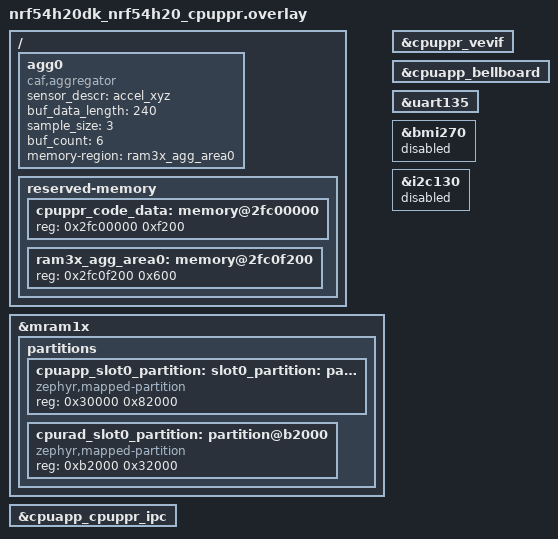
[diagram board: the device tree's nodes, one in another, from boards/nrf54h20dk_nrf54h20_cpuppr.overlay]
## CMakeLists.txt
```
#
# Copyright (c) 2024 Nordic Semiconductor ASA
#
# SPDX-License-Identifier: LicenseRef-Nordic-5-Clause
#

cmake_minimum_required(VERSION 3.20.0)

################################################################################

find_package(Zephyr REQUIRED HINTS $ENV{ZEPHYR_BASE})

if(NOT EXISTS "${CMAKE_CURRENT_SOURCE_DIR}/configuration/${NORMALIZED_BOARD_TARGET}")
  message(FATAL_ERROR
          "Board ${BOARD} is not supported.\n"
          "Please make sure board specific configuration files are added to "
          "${CMAKE_CURRENT_SOURCE_DIR}/configuration/${BOARD}")
endif()

set(REMOTE_INC_DIR "${CMAKE_CURRENT_SOURCE_DIR}/configuration/${NORMALIZED_BOARD_TARGET}")
string(CONFIGURE ${REMOTE_INC_DIR} REMOTE_INC_DIR)

project(remote)

target_sources(app PRIVATE src/main.c)

# Add include directory for board specific CAF def files
zephyr_include_directories(
  ../configuration/common
  /configuration
  ${REMOTE_INC_DIR}
)

# Add subdirectory from common part.
add_subdirectory(../common/src/modules ${CMAKE_CURRENT_BINARY_DIR}/common/src/module)
```

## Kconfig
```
#
# Copyright (c) 2024 Nordic Semiconductor ASA
#
# SPDX-License-Identifier: LicenseRef-Nordic-5-Clause
#

menu "Machine learning application (remote core)"

rsource "../common/Kconfig"

endmenu

menu "Zephyr Kernel"
source "Kconfig.zephyr"
endmenu
```

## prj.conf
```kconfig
#
# Copyright (c) 2024 Nordic Semiconductor ASA
#
# SPDX-License-Identifier: LicenseRef-Nordic-5-Clause
#
################################################################################
# Application configuration

CONFIG_CAF=y

CONFIG_CAF_INIT_LOG_SENSOR_EVENTS=n

CONFIG_CAF_SENSOR_MANAGER=y

CONFIG_APP_EVENT_MANAGER=y
CONFIG_EVENT_MANAGER_PROXY=y
CONFIG_HEAP_MEM_POOL_SIZE=4096
CONFIG_REBOOT=y

CONFIG_SENSOR=y

CONFIG_IPC_SERVICE=y
CONFIG_MBOX=y

################################################################################
# Debug configuration

CONFIG_ASSERT=y
CONFIG_RESET_ON_FATAL_ERROR=n

CONFIG_LOG=y
```

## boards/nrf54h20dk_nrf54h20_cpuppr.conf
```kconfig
#
# Copyright (c) 2024 Nordic Semiconductor ASA
#
# SPDX-License-Identifier: LicenseRef-Nordic-5-Clause
#
################################################################################
# Application configuration

CONFIG_ML_APP_SENSOR_EVENT_DESCR="accel_xyz"

CONFIG_ML_APP_EVENT_PROXY=y
CONFIG_ML_APP_REMOTE_CORE_INITIALIZATION_TIMEOUT=10000

CONFIG_SIZE_OPTIMIZATIONS=y

################################################################################
# System configuration

CONFIG_TIMESLICING=n

# LIBC minimal configuration
CONFIG_MINIMAL_LIBC=y
CONFIG_MINIMAL_LIBC_TIME=n
CONFIG_COMMON_LIBC_MALLOC=n
CONFIG_MINIMAL_LIBC_NON_REENTRANT_FUNCTIONS=n

CONFIG_HEAP_MEM_POOL_SIZE=512
CONFIG_EVENT_MANAGER_PROXY=y
# Higher timouts are required.
CONFIG_EVENT_MANAGER_PROXY_BIND_TIMEOUT_MS=4000

CONFIG_GPIO=y

################################################################################
# Debug configuration
CONFIG_LOG=y
CONFIG_LOG_MODE_MINIMAL=y

CONFIG_ASSERT=n
CONFIG_ASSERT_VERBOSE=n
CONFIG_BOOT_BANNER=n
CONFIG_NCS_BOOT_BANNER=n

CONFIG_DEBUG=n
CONFIG_PRINTK=y

CONFIG_MAIN_STACK_SIZE=1024
CONFIG_IDLE_STACK_SIZE=128
CONFIG_ISR_STACK_SIZE=1024

# Interrupts
CONFIG_DYNAMIC_INTERRUPTS=n
CONFIG_IRQ_OFFLOAD=n

# Memory protection
CONFIG_HW_STACK_PROTECTION=n
CONFIG_THREAD_STACK_INFO=n
CONFIG_THREAD_CUSTOM_DATA=n
CONFIG_FPU=n

# ADXXL362 sensor configuration
CONFIG_ADXL362=y
CONFIG_ADXL362_ACCEL_RANGE_8G=y
CONFIG_ADXL362_ACCEL_ODR_100=y
CONFIG_ADXL362_TRIGGER_GLOBAL_THREAD=y
CONFIG_ADXL362_INACTIVITY_THRESHOLD=0
CONFIG_ADXL362_ACTIVITY_THRESHOLD=110
CONFIG_ADXL362_ABS_REF_MODE=1
```

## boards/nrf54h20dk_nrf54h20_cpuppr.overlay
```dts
/*
 * Copyright (c) 2024 Nordic Semiconductor ASA
 *
 * SPDX-License-Identifier: LicenseRef-Nordic-5-Clause
 */

/ {
	agg0: agg0 {
		compatible = "caf,aggregator";
		sensor_descr = "accel_xyz";
		buf_data_length = <240>;
		sample_size = <3>;
		buf_count = <6>;
		memory-region = <&ram3x_agg_area0>;
		status = "okay";
	};

	reserved-memory {
		cpuppr_code_data: memory@2fc00000 {
			reg = <0x2fc00000 0xf200>;
		};

		ram3x_agg_area0: memory@2fc0f200 {
			reg = <0x2fc0f200 0x600>;
		};
	};
};

/delete-node/ &cpuapp_slot0_partition;
/delete-node/ &cpurad_slot0_partition;

/* This duplicates the Application core configuration to build PPR image under valid address. */
&mram1x {
	partitions {
		ranges;

		cpuapp_slot0_partition: slot0_partition: partition@30000 {
			compatible = "zephyr,mapped-partition";
			reg = <0x30000 0x82000>;
		};

		cpurad_slot0_partition: partition@b2000 {
			compatible = "zephyr,mapped-partition";
			reg = <0xb2000 0x32000>;
		};
	};
};

ipc1: &cpuapp_cpuppr_ipc {
	status = "okay";
};

&cpuppr_vevif {
	status = "okay";
};

&cpuapp_bellboard {
	status = "okay";
};

&uart135 {
	/delete-property/ hw-flow-control;
};

/* Disable unused sensors and peripherals. */
/delete-node/ &bme688;

&bmi270 {
	status = "disabled";
};

&i2c130 {
	status = "disabled";
};
```

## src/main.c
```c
/*
 * Copyright (c) 2024 Nordic Semiconductor ASA
 *
 * SPDX-License-Identifier: LicenseRef-Nordic-5-Clause
 */

#include <zephyr/kernel.h>
#include <app_event_manager.h>

#define MODULE main
#include <caf/events/module_state_event.h>

#include <zephyr/logging/log.h>
LOG_MODULE_REGISTER(MODULE);

int main(void)
{
	LOG_INF("Machine learning: %s started", CONFIG_BOARD_TARGET);

	if (app_event_manager_init()) {
		LOG_ERR("Application Event Manager initialization failed");
		__ASSERT_NO_MSG(false);
	} else {
		module_set_state(MODULE_STATE_READY);
	}
	return 0;
}
```
